# STM32U575 register map
File version: 1.4
CPU: CM33 r0p1, little endian, MPU, FPU, 4 interrupt priority bits
Registers are 32-bit, read-write, reset 0x0 unless marked. A register's access mark holds for its fields unless they carry their own. Offsets are from the block's base; [hi:lo] are bit positions; lines under a group give offsets from that group; {n}, {i} and the like mark numbered series; 'fields as' and 'values as' point back to an identical list.

## ADC1
Base 0x42028000
Same registers: SEC_ADC1 0x52028000
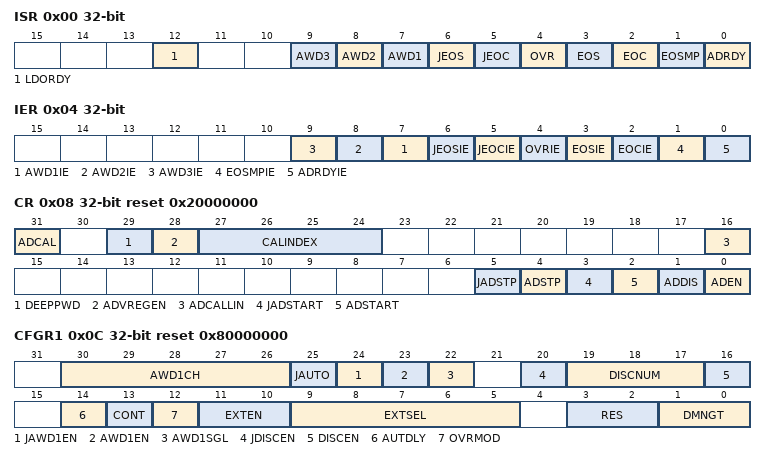
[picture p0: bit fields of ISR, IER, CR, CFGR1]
0x00 ISR access per field — ADC interrupt and status register
  [12] LDORDY ro — ADC voltage regulator ready This bit is set by hardware. It indicates that the ADC internal supply is ready. The ADC is available after tADCVREG_SETUP time.
    0=Disabled (ADC voltage regulator disabled); 1=Enabled (ADC voltage regulator enabled)
  [n+6] AWD{n} (n=1..3) rw — Analog watchdog {n} flag
    on read: 0=NoEvent (No analog watchdog x event occurred (or the flag event was already acknowledged and cleared by software)); 1=Event (Analog watchdog x event occurred) | on write: 1=Clear the analog watchdog x event flag
  [6] JEOS rw — Injected channel end of sequence flag This bit is set by hardware at the end of the conversions of all injected channels in the group. It is cleared by software writing 1 to it.
    on read: 0=NotComplete (Injected conversion sequence not complete (or the flag event was already acknowledged and cleared by software)); 1=Complete (Injected conversions sequence complete) | on write: 1=Clear the injected conversion sequence flag
  [5] JEOC rw — Injected channel end of conversion flag This bit is set by hardware at the end of each injected conversion of a channel when a new data is available in the corresponding ADC_JDRy register. It is cleared by software writing 1 to it or by reading the corresponding ADC_JDRy register
    on read: 0=NotComplete (Injected channel conversion not complete (or the flag event was already acknowledged and cleared by software)); 1=Complete (Injected channel conversion complete) | on write: 1=Clear the injected channel conversion flag
  [4] OVR rw — ADC overrun This bit is set by hardware when an overrun occurs on a regular channel, meaning that a new conversion has completed while the EOC flag was already set. It is cleared by software writing 1 to it.
    on read: 0=No overrun occurred (or the flag event was already acknowledged and cleared by software); 1=Overrun has occurred | on write: 1=Clear the overrun flag
  [3] EOS rw — End of regular sequence flag This bit is set by hardware at the end of the conversions of a regular sequence of channels. It is cleared by software writing 1 to it.
    on read: 0=NotComplete (Regular conversions sequence not complete (or the flag event was already acknowledged and cleared by software)); 1=Complete (Regular conversions sequence complete) | on write: 1=Clear the regular conversion sequence flag
  [2] EOC rw — End of conversion flag This bit is set by hardware at the end of each regular conversion of a channel when a new data is available in the ADC_DR register. It is cleared by software writing 1 to it or by reading the ADC_DR register
    on read: 0=NotComplete (Regular channel conversion not complete (or the flag event was already acknowledged and cleared by software)); 1=Complete (Regular channel conversion complete) | on write: 1=Clear the regular channel conversion flag
  [1] EOSMP rw — End of sampling flag This bit is set by hardware during the conversion of any channel (only for regular channels), at the end of the sampling phase.
    on read: 0=NotAtEnd (Not at the end of the sampling phase (or the flag event was already acknowledged and cleared by software)); 1=AtEnd (End of sampling phase reached) | on write: 1=Clear the sampling phase flag
  [0] ADRDY rw — ADC ready This bit is set by hardware after the ADC has been enabled (bit ADEN = 1) and when the ADC reaches a state where it is ready to accept conversion requests. It is cleared by software writing 1 to it.
    on read: 0=NotReady (ADC not yet ready to start conversion (or the flag event was already acknowledged and cleared by software)); 1=Ready (ADC is ready to start conversion) | on write: 1=Clear the ADC ready flag
0x04 IER — ADC interrupt enable register
  [n+6] AWD{n}IE (n=1..3) — Analog watchdog {n} interrupt enable
    0=Disabled (Analog watchdog x interrupt disabled); 1=Enabled (Analog watchdog x interrupt enabled)
  [6] JEOSIE — End of injected sequence of conversions interrupt enable This bit is set and cleared by software to enable/disable the end of injected sequence of conversions interrupt. Note: Software is allowed to write this bit only when JADSTART = 0 (which ensures that no injected conversion is ongoing).
    0=Disabled (JEOS interrupt disabled); 1=Enabled (JEOS interrupt enabled. An interrupt is generated when the JEOS bit is set.)
  [5] JEOCIE — End of injected conversion interrupt enable This bit is set and cleared by software to enable/disable the end of an injected conversion interrupt. Note: Software is allowed to write this bit only when JADSTART = 0 (which ensures that no regular conversion is ongoing).
    0=Disabled (JEOC interrupt disable); 1=Enabled (JEOC interrupt enabled. An interrupt is generated when the JEOC bit is set.)
  [4] OVRIE — Overrun interrupt enable This bit is set and cleared by software to enable/disable the Overrun interrupt of a regular conversion. Note: Software is allowed to write this bit only when ADSTART = 0 (which ensures that no regular conversion is ongoing).
    0=Disabled (Overrun interrupt disabled); 1=Enabled (Overrun interrupt enabled. An interrupt is generated when the OVR bit is set.)
  [3] EOSIE — End of regular sequence of conversions interrupt enable This bit is set and cleared by software to enable/disable the end of regular sequence of conversions interrupt. Note: Software is allowed to write this bit only when ADSTART = 0 (which ensures that no regular conversion is ongoing).
    0=Disabled (EOS interrupt disabled); 1=Enabled (EOS interrupt enabled. An interrupt is generated when the EOS bit is set.)
  [2] EOCIE — End of regular conversion interrupt enable This bit is set and cleared by software to enable/disable the end of a regular conversion interrupt. Note: Software is allowed to write this bit only when ADSTART = 0 (which ensures that no regular conversion is ongoing).
    0=Disabled (EOC interrupt disabled); 1=Enabled (EOC interrupt enabled. An interrupt is generated when the EOC bit is set.)
  [1] EOSMPIE — End of sampling flag interrupt enable for regular conversions This bit is set and cleared by software to enable/disable the end of the sampling phase interrupt for regular conversions. Note: Software is allowed to write this bit only when ADSTART = 0 (which ensures that no regular conversion is ongoing).
    0=Disabled (EOSMP interrupt disabled); 1=Enabled (EOSMP interrupt enabled. An interrupt is generated when the EOSMP bit is set.)
  [0] ADRDYIE — ADC ready interrupt enable This bit is set and cleared by software to enable/disable the ADC Ready interrupt. Note: Software is allowed to write this bit only when ADSTART = 0 and JADSTART = 0 (which ensures that no conversion is ongoing).
    0=Disabled (ADRDY interrupt disabled); 1=Enabled (ADRDY interrupt enabled. An interrupt is generated when the ADRDY bit is set.)
0x08 CR reset 0x20000000 — ADC control register
  [31] ADCAL — ADC calibration This bit is set by software to start the ADC calibration. It is cleared by hardware after calibration is complete. Note: The software is allowed to launch a calibration by setting ADCAL only when ADEN = 0.
    on read: 0=NotCalibrating (Calibration complete); 1=Calibrating (Calibration in progress) | on write: 1=StartCalibration (Calibrate the ADC)
  [29] DEEPPWD — Deep-power-down enable This bit is set and cleared by software to put the ADC in Deep-power-down mode. Note: The software is allowed to write this bit only when the ADC is disabled (ADCAL = 0, JADSTART = 0, JADSTP = 0, ADSTART = 0, ADSTP = 0, ADDIS = 0 and ADEN = 0).
    0=Disabled (ADC not in deep-power down); 1=Enabled (ADC in deep-power down)
  [28] ADVREGEN — ADC voltage regulator enable This bits is set by software to enable the ADC voltage regulator. Before performing any operation such as launching a calibration or enabling the ADC, the ADC voltage regulator must first be enabled and the software must wait for the regulator start-up time. For more details about the ADC voltage regulator enable and disable sequences, refer to (ADVREGEN). The software can program this bit field only when the ADC is disabled (ADCAL = 0, JADSTART = 0, ADSTART = 0, ADSTP = 0, ADDIS = 0 and ADEN = 0).
    values as ISR.LDORDY
  [27:24] CALINDEX — Calibration factor This bitfield controls the calibration factor to be read or written. Calibration index 0 is dedicated to single-ended and differential offsets, calibration index 1 to 7 to the linearity calibration factors, and index 8 to the internal offset: Others: Reserved, must not be used Note: ADC_CALFACT2[31:0] correspond to the location of CALINDEX[3:0] calibration factor data (see for details).
    0=OffsetCalFactor (Offset calibration factor); {v}=CalFactor{v} (Calibration factor {v}) (v=1..6); 7=CalFactor7 (Calibration factor 7 and (write access only) internal offset); 8=Internal offset (read access only); 9=Calibration mode selection
  [16] ADCALLIN — Linearity calibration This bit is set and cleared by software to enable the linearity calibration. Note: The software is allowed to write this bit only when the ADC is disabled and is not calibrating (ADCAL = 0, JADSTART = 0, JADSTP = 0, ADSTART = 0, ADSTP = 0, ADDIS = 0 and ADEN = 0).
    0=Disabled (Writing ADCAL launches a calibration without the linearity calibration); 1=Enabled (Writing ADCAL launches a calibration with he linearity calibration)
  [5] JADSTP — ADC stop of injected conversion command This bit is set by software to stop and discard an ongoing injected conversion (JADSTP Command). It is cleared by hardware when the conversion is effectively discarded and the ADC injected sequence and triggers can be re-configured. The ADC is then ready to accept a new start of injected conversions (JADSTART command). Note: The software is allowed to set JADSTP only when JADSTART = 1 and ADDIS = 0 (ADC is enabled and eventually converting an injected conversion and there is no pending request to disable the ADC). In Auto-injection mode (JAUTO = 1), setting ADSTP bit aborts both regular and injected conversions (do not use JADSTP)
    on read: 0=NotStopped (No ADC stop injected conversion command ongoing); 1=Stopped (ADSTP command is in progress) | on write: 1=Stop injected conversions ongoing
  [4] ADSTP — ADC stop of regular conversion command This bit is set by software to stop and discard an ongoing regular conversion (ADSTP Command). It is cleared by hardware when the conversion is effectively discarded and the ADC regular sequence and triggers can be re-configured. The ADC is then ready to accept a new start of regular conversions (ADSTART command). Note: The software is allowed to set ADSTP only when ADSTART = 1 and ADDIS = 0 (ADC is enabled and eventually converting a regular conversion and there is no pending request to disable the ADC). In Auto-injection mode (JAUTO = 1), setting ADSTP bit aborts both regular and injected conversions (do not use JADSTP).
    on read: 0=NotStopping (No ADC stop regular conversion command ongoing); 1=Stopping (ADSTP command is in progress) | on write: 1=StopConversion (Stop regular conversions ongoing)
  [3] JADSTART — ADC start of injected conversion This bit is set by software to start ADC conversion of injected channels. Depending on the configuration bits JEXTEN[1:0], a conversion starts immediately (software trigger configuration) or once an injected hardware trigger event occurs (hardware trigger configuration). It is cleared by hardware: in Single conversion mode when software trigger is selected (JEXTSEL = 0x0): at the assertion of the end of injected conversion sequence (JEOS) flag. in all cases: after the execution of the JADSTP command, at the same time as JADSTP is cleared by hardware. Note: The software is allowed to set JADSTART only when ADEN = 1 and ADDIS = 0 (ADC is enabled and there is no pending request to disable the ADC). In Auto-injection mode (JAUTO = 1), regular and auto-injected conversions are started by setting bit ADSTART (JADSTART must be kept cleared)
    on read: 0=NotActive (No ADC injected conversion is ongoing); 1=Active (ADC is operating and eventually converting an injected channel) | on write: 1=Start injected conversions
  [2] ADSTART — ADC start of regular conversion This bit is set by software to start ADC conversion of regular channels. Depending on the configuration bits EXTEN[1:0], a conversion starts immediately (software trigger configuration) or once a regular hardware trigger event occurs (hardware trigger configuration). It is cleared by hardware: in Single conversion mode (CONT = 0, DISCEN = 0) when software trigger is selected (EXTEN[1:0] = 0x0): at the assertion of the end of regular conversion sequence (EOS) flag. In Discontinuous conversion mode (CONT = 0, DISCEN = 1), when the software trigger is selected (EXTEN[1:0] = 0x0): at the end of conversion (EOC) flag. in all other cases: after the execution of the ADSTP command, at the same time that ADSTP is cleared by hardware. Note: The software is allowed to set ADSTART only when ADEN = 1 and ADDIS = 0 (ADC is enabled and there is no pending request to disable the ADC) In Auto-injection mode (JAUTO = 1), regular and auto-injected conversions are started by setting bit ADSTART (JADSTART must be kept cleared)
    on read: 0=NotActive (No ADC regular conversion is ongoing); 1=Active (ADC is operating and eventually converting a regular channel) | on write: 1=Start regular conversions
  [1] ADDIS — ADC disable command This bit is set by software to disable the ADC (ADDIS command) and put it into power-down state (OFF state). It is cleared by hardware once the ADC is effectively disabled (ADEN is also cleared by hardware at this time). Note: The software is allowed to set ADDIS only when ADEN = 1 and both ADSTART = 0 and JADSTART = 0 (which ensures that no conversion is ongoing)
    on read: 0=NotOngoing (No ADDIS command ongoing); 1=InProgress (An ADDIS command is in progress) | on write: 1=Disable the ADC
  [0] ADEN — ADC enable control This bit is set by software to enable the ADC. The ADC is effectively ready to operate once the flag ADRDY has been set. It is cleared by hardware when the ADC is disabled, after the execution of the ADDIS command. Note: The software is allowed to set ADEN only when all bits of ADC_CR registers are 0 (ADCAL = 0, JADSTART = 0, ADSTART = 0, ADSTP = 0, ADDIS = 0 and ADEN = 0) except for bit ADVREGEN which must be 1 (and the software must have wait for the startup time of the voltage regulator)
    on read: 0=Disabled (ADC is disabled); 1=Enabled (ADC is enabled) | on write: 1=Enabled (Enable the ADC)
0x0C CFGR1 reset 0x80000000 — ADC configuration register
  [30:26] AWD1CH range 0..19 — Analog watchdog 1 channel selection These bits are set and cleared by software. They select the input channel to be guarded by the analog watchdog. ..... Others: Reserved, must not be used Note: The channel selected by AWD1CH must be also selected into the SQRi or JSQRi registers. Software is allowed to write these bits only when ADSTART = 0 and JADSTART = 0 (which ensures that no conversion is ongoing).
  [25] JAUTO — Automatic injected group conversion This bit is set and cleared by software to enable/disable automatic injected group conversion after regular group conversion. Note: The software is allowed to write this bit only when ADSTART = 0 and JADSTART = 0 (which ensures that no regular nor injected conversion is ongoing).
    0=Disabled (Automatic injected group conversion disabled); 1=Enabled (Automatic injected group conversion enabled)
  [24] JAWD1EN — Analog watchdog 1 enable on injected channels This bit is set and cleared by software Note: The software is allowed to write this bit only when JADSTART = 0 (which ensures that no injected conversion is ongoing).
    0=Disabled (Analog watchdog 1 disabled on injected channels); 1=Enabled (Analog watchdog 1 enabled on injected channels)
  [23] AWD1EN — Analog watchdog 1 enable on regular channels This bit is set and cleared by software Note: The software is allowed to write this bit only when ADSTART = 0 (which ensures that no regular conversion is ongoing).
    0=Disabled (Analog watchdog 1 disabled on regular channels); 1=Enabled (Analog watchdog 1 enabled on regular channels)
  [22] AWD1SGL — Enable the watchdog 1 on a single channel or on all channels This bit is set and cleared by software to enable the analog watchdog on the channel identified by the AWD1CH[4:0] bits or on all the channels Note: The software is allowed to write these bits only when ADSTART = 0 and JADSTART = 0 (which ensures that no conversion is ongoing).
    0=AllChannels (Analog watchdog 1 enabled on all channels); 1=SingleChannel (Analog watchdog 1 enabled on a single channel)
  [20] JDISCEN — Discontinuous mode on injected channels This bit is set and cleared by software to enable/disable discontinuous mode on the injected channels of a group. Note: The software is allowed to write this bit only when JADSTART = 0 (which ensures that no injected conversion is ongoing). It is not possible to use both auto-injected mode and discontinuous mode simultaneously: the bits DISCEN and JDISCEN must be kept cleared by software when JAUTO is set.
    0=Disabled (Discontinuous mode on injected channels disabled); 1=Enabled (Discontinuous mode on injected channels enabled)
  [19:17] DISCNUM — Discontinuous mode channel count These bits are written by software to define the number of regular channels to be converted in discontinuous mode, after receiving an external trigger. ... Note: The software is allowed to write these bits only when ADSTART = 0 (which ensures that no regular conversion is ongoing).
    0=n1 (1 channel); {v}=n{v+1} ({v+1} channels) (v=1..7)
  [16] DISCEN — Discontinuous mode for regular channels This bit is set and cleared by software to enable/disable Discontinuous mode for regular channels. Note: It is not possible to have both discontinuous mode and continuous mode enabled: it is forbidden to set both DISCEN = 1 and CONT = 1. It is not possible to use both auto-injected mode and discontinuous mode simultaneously: the bits DISCEN and JDISCEN must be kept cleared by software when JAUTO is set. The software is allowed to write this bit only when ADSTART = 0 (which ensures that no regular conversion is ongoing).
    0=Disabled (Discontinuous mode for regular channels disabled); 1=Enabled (Discontinuous mode for regular channels enabled)
  [14] AUTDLY — Delayed conversion mode This bit is set and cleared by software to enable/disable the Auto Delayed Conversion mode.. Note: The software is allowed to write this bit only when ADSTART = 0 and JADSTART = 0 (which ensures that no conversion is ongoing).
    0=Disabled (Auto-delayed conversion mode off); 1=Enabled (Auto-delayed conversion mode on)
  [13] CONT — Single / continuous conversion mode for regular conversions This bit is set and cleared by software. If it is set, regular conversion takes place continuously until it is cleared. Note: It is not possible to have both discontinuous mode and continuous mode enabled: it is forbidden to set both DISCEN = 1 and CONT = 1. The software is allowed to write this bit only when ADSTART = 0 (which ensures that no regular conversion is ongoing).
    0=Single conversion mode; 1=Continuous conversion mode
  [12] OVRMOD — Overrun Mode This bit is set and cleared by software and configure the way data overrun is managed. Note: The software is allowed to write this bit only when ADSTART = 0 (which ensures that no regular conversion is ongoing).
    0=Preserve (ADC_DR register is preserved with the old data when an overrun is detected); 1=Overwrite (ADC_DR register is overwritten with the last conversion result when an overrun is detected)
  [11:10] EXTEN — External trigger enable and polarity selection for regular channels These bits are set and cleared by software to select the external trigger polarity and enable the trigger of a regular group. Note: The software is allowed to write these bits only when ADSTART = 0 (which ensures that no regular conversion is ongoing).
    0=Disabled (Hardware trigger detection disabled (conversions can be launched by software)); 1=RisingEdge (Hardware trigger detection on the rising edge); 2=FallingEdge (Hardware trigger detection on the falling edge); 3=BothEdges (Hardware trigger detection on both the rising and falling edges)
  [9:5] EXTSEL — External trigger selection for regular group These bits select the external event used to trigger the start of conversion of a regular group: ... Refer to the ADC external trigger for regular channels in signals for details on trigger mapping. Note: The software is allowed to write these bits only when ADSTART = 0 (which ensures that no regular conversion is ongoing).
    0=TIM1_OC1; 1=TIM1_OC2; 2=TIM1_OC3; 3=TIM2_OC2; 4=TIM3_TRGO; 5=TIM4_OC4; 6=EXTI11; 7=TIM8_TRGO; 8=TIM8_TRGO2; 9=TIM1_TRGO; 10=TIM1_TRGO2; 11=TIM2_TRGO; 12=TIM4_TRGO; 13=TIM6_TRGO; 14=TIM15_TRGO; 15=TIM3_OC4; 16=EXTI15; 18=LPTIM1_CH1; 19=LPTIM2_CH1; 20=LPTIM3_CH1; 21=LPTIM4_OUT
  [3:2] RES — Data resolution These bits are written by software to select the resolution of the conversion. Note: The software is allowed to write these bits only when ADSTART = 0 and JADSTART = 0 (which ensures that no conversion is ongoing).
    0=FourteenBit (14 bits); 1=TwelveBit (12 bits); 2=TenBit (10 bits); 3=EightBit (8 bits)
  [1:0] DMNGT — Data management configuration This bit is set and cleared by software to select how the ADC interface output data are managed. Note: The software is allowed to write this bit only when ADSTART = 0 and JADSTART = 0 (which ensures that no conversion is ongoing).
    0=DR (Store output data in DR only); 1=DMA One Shot Mode selected; 2=DFSDM (DFSDM mode selected); 3=DMA Circular Mode selected
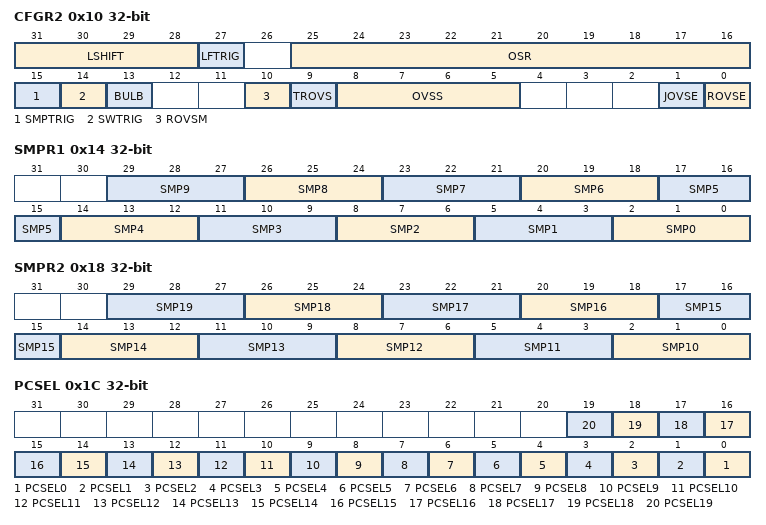
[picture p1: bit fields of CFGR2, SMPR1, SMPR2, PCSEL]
0x10 CFGR2 — ADC configuration register 2
  [31:28] LSHIFT — Left shift factor This bitfield is set and cleared by software to define the left shifting applied to the final result with or without oversampling. Note: The software is allowed to write this bit only when ADSTART = 0 (which ensures that no conversion is ongoing).
  [27] LFTRIG — Low-frequency trigger This bit is set and cleared by software Note: The software is allowed to write this bit only when ADSTART = 0 (which ensures that no conversion is ongoing).
    0=Disabled (Low-frequency trigger mode disabled); 1=Enabled (Low-frequency trigger mode enabled)
  [25:16] OSR — Oversampling ratio This bitfield is set and cleared by software to define the oversampling ratio. 2: 3x ... 1023: 1024x Note: The software is allowed to write this bit only when ADSTART = 0 (which ensures that no conversion is ongoing).
  [15] SMPTRIG — Sampling time control trigger mode This bit is set and cleared by software to enable the sampling time control trigger mode. The sampling time starts on the trigger rising edge, and the conversion on the trigger falling edge. EXTEN[1:0] bits must be set to 01. BULB bit must not be set when the SMPTRIG bit is set. When EXTEN[1:0] bits is set to 00, set SWTRIG to start the sampling and clear SWTRIG bit to start the conversion. Note: The software is allowed to write this bit only when ADSTART = 0 (which ensures that no conversion is ongoing).
    0=Disabled (Sampling time control trigger mode disabled); 1=Enabled (Sampling time control trigger mode enabled)
  [14] SWTRIG — Software trigger bit for sampling time control trigger mode This bit is set and cleared by software to enable the bulb sampling mode. Note: The software is allowed to write this bit only when ADSTART = 0 (which ensures that no conversion is ongoing).
    0=Disabled (Software trigger starts the conversion for sampling time control trigger mode); 1=Enabled (Software trigger starts the sampling for sampling time control trigger mode)
  [13] BULB — Bulb sampling mode This bit is set and cleared by software to select the bulb sampling mode. SMPTRIG bit must not be set when the BULB bit is set. The very first ADC conversion is performed with the sampling time specified in SMPx bits. Note: The software is allowed to write this bit only when ADSTART = 0 (which ensures that no conversion is ongoing).
    0=Disabled (Bulb sampling mode disabled); 1=Enabled (Bulb sampling mode enabled. The sampling period starts just after the previous end of the conversion.)
  [10] ROVSM — Regular Oversampling mode This bit is set and cleared by software to select the regular oversampling mode. Note: The software is allowed to write this bit only when ADSTART = 0 (which ensures that no conversion is ongoing).
    0=Continued (When injected conversions are triggered, the oversampling is temporary stopped and continued after the injection sequence (oversampling buffer is maintained during injected sequence)); 1=Resumed (When injected conversions are triggered, the current oversampling is aborted and resumed from start after the injection sequence (oversampling buffer is zeroed by injected sequence start))
  [9] TROVS — Triggered Regular Oversampling This bit is set and cleared by software to enable triggered oversampling Note: The software is allowed to write this bit only when ADSTART = 0 (which ensures that no conversion is ongoing).
    0=Automatic (All oversampled conversions for a channel are done consecutively following a trigger); 1=Triggered (Each oversampled conversion for a channel needs a new trigger)
  [8:5] OVSS range 0..11 — Oversampling right shift This bit field is set and cleared by software to define the right shifting applied to the raw oversampling result. Others: Reserved, must not be used. Note: The software is allowed to write these bits only when ADSTART = 0 (which ensures that no conversion is ongoing).
  [1] JOVSE — Injected Oversampling Enable This bit is set and cleared by software to enable injected oversampling. Note: The software is allowed to write this bit only when ADSTART = 0 and JADSTART = 0 (which ensures that no conversion is ongoing)
    0=Disabled (Injected oversampling disabled); 1=Enabled (Injected oversampling enabled)
  [0] ROVSE — Regular Oversampling Enable This bit is set and cleared by software to enable regular oversampling. Note: The software is allowed to write this bit only when ADSTART = 0 and JADSTART = 0 (which ensures that no conversion is ongoing)
    0=Disabled (Regular oversampling disabled); 1=Enabled (Regular oversampling enabled)
0x14 SMPR1 — ADC sample time register 1
  [3n+2:3n] SMP{n} (n=0..9) — Channel {n} sample time selection
    0=Cycles5 (5 ADC clock cycles); 1=Cycles6 (6 ADC clock cycles); 2=Cycles12 (12 ADC clock cycles); 3=Cycles20 (20 ADC clock cycles); 4=Cycles36 (36 ADC clock cycles); 5=Cycles68 (68 ADC clock cycles); 6=Cycles391 (391 ADC clock cycles); 7=Cycles814 (814 ADC clock cycles)
0x18 SMPR2 — ADC sample time register 2
  [3n-28:3n-30] SMP{n} (n=10..19) — Channel {n} sample time selection
    values as SMPR1.SMP0
0x1C PCSEL — ADC channel preselection register
  [all] fields
    0=NotPreselected (Input channel x is not preselected for conversion, the ADC conversion of this channel shows a wrong result.); 1=Preselected (Input channel x is preselected for conversion)
  [n] PCSEL{n} (n=0..19) — Channel i (VINP[i]) preselection These bits are written by software to preselect the input channel I/O instance to be converted. Note: The software is allowed to write these bits only when ADSTART = 0 and JADSTART = 0 (which ensures that no conversion is ongoing).
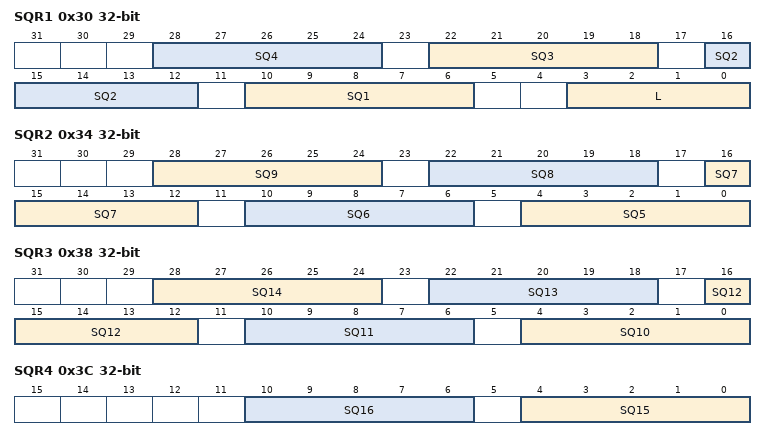
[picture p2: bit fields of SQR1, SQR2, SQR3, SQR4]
0x30 SQR1 — ADC regular sequence register 1
  [6n+4:6n] SQ{n} (n=1..4) — {n} conversion in regular sequence
  [3:0] L — Regular channel sequence length These bits are written by software to define the total number of conversions in the regular channel conversion sequence. ... Note: The software is allowed to write these bits only when ADSTART = 0 (which ensures that no regular conversion is ongoing).
0x34 SQR2 — ADC regular sequence register 2
  [6n-26:6n-30] SQ{n} (n=5..9) — {n} conversion in regular sequence
0x38 SQR3 — ADC regular sequence register 3
  [6n-56:6n-60] SQ{n} (n=10..14) — {n} conversion in regular sequence
0x3C SQR4 — ADC regular sequence register 4
  [6n-86:6n-90] SQ{n} (n=15..16) — {n} conversion in regular sequence
0x40 DR ro — ADC regular Data Register
  [31:0] RDATA — Regular data converted These bits are read-only. They contain the conversion result from the last converted regular channel. The data are left- or right-aligned as described in .
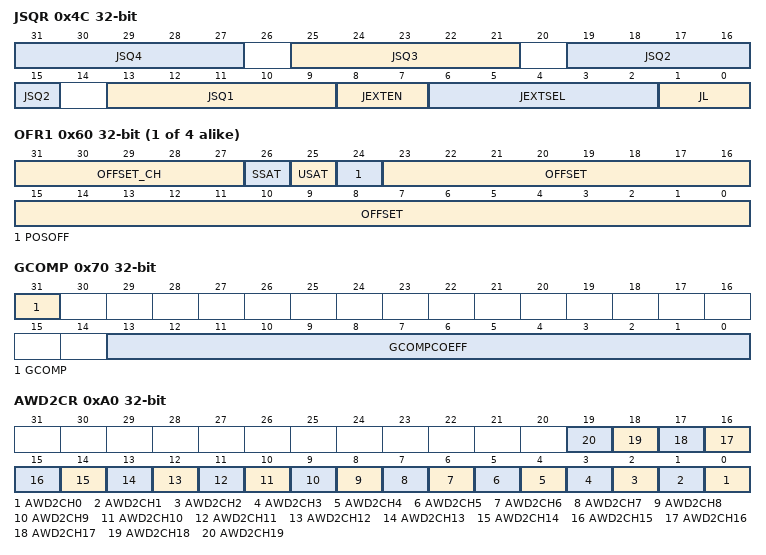
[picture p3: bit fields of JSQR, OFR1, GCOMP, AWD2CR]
0x4C JSQR — ADC injected sequence register
  [6n+7:6n+3] JSQ{n} (n=1..4) — {n} conversion in injected sequence
  [8:7] JEXTEN — External trigger enable and polarity selection for injected channels These bits are set and cleared by software to select the external trigger polarity and enable the trigger of an injected group. Note: The software is allowed to write these bits only when JADSTART = 0 (which ensures that no injected conversion is ongoing.
    values as CFGR1.EXTEN
  [6:2] JEXTSEL — External trigger selection for injected group These bits select the external event used to trigger the start of conversion of an injected group: ... Refer to the ADC external trigger for injected channels in internal signals for details on trigger mapping. Note: The software is allowed to write these bits only when JADSTART = 0 (which ensures that no injected conversion is ongoing.
    0=TIM1_TRGO; 1=TIM1_OC4; 2=TIM2_TRGO; 3=TIM2_OC1; 4=TIM3_OC4; 5=TIM4_TRGO; 6=EXTI15; 7=TIM8_OC4; 8=TIM1_TRGO2; 9=TIM8_TRGO; 10=TIM8_TRGO2; 11=TIM3_OC3; 12=TIM3_TRGO; 13=TIM3_OC1; 14=TIM6_TRGO; 15=TIM15_TRGO; 16=LPTIM1_CH2; 17=LPTIM2_CH2; 18=LPTIM3_CH1; 19=LPTIM4_OUT1
  [1:0] JL — Injected channel sequence length These bits are written by software to define the total number of conversions in the injected channel conversion sequence. Note: The software is allowed to write these bits only when JADSTART = 0 (which ensures that no injected conversion is ongoing.
{0x5C+4i} OFR{i} (i=1..4) — ADC offset register
  [31:27] OFFSET_CH — Channel selection for the data offset y These bits are written by software to define the channel to which the offset programmed into OFFSETy[25:0] bits applies. Note: The software is allowed to write these bits only when ADSTART = 0 and JADSTART = 0 (which ensures that no conversion is ongoing). If OFFSETy_EN bit is set, it is not allowed to select the same channel in different ADC_OFRy registers.
  [26] SSAT — Signed saturation enable This bit is written by software to enable or disable the Signed saturation feature. (see OFFSETy_CH, OVSS, LSHIFT, USAT, SSAT) for details). Note: The software is allowed to write this bit only when ADSTART = 0 and JADSTART = 0 (which ensures that no conversion is ongoing).
    0=Disabled (Offset is subtracted maintaining data integrity and extending converted data size (9-bit and 15-bit signed format)); 1=Enabled (Offset is subtracted and result is saturated to maintain converted data size)
  [25] USAT — Unsigned saturation enable This bit is written by software to enable or disable the unsigned saturation feature. Note: The software is allowed to write this bit only when ADSTART = 0 and JADSTART = 0 (which ensures that no conversion is ongoing).
    0=Disabled (Offset is subtracted maintaining data integrity and keeping converted data size); 1=Enabled (Offset is subtracted and result is saturated to maintain converted data size)
  [24] POSOFF — offset sign This bit is set and cleared by software to enable the positive offset. Note: The software is allowed to write these bits only when ADSTART = 0 and JADSTART = 0 (which ensures that no conversion is ongoing).
    0=Negative offset; 1=Positive offset
  [23:0] OFFSET — Data offset y for the channel programmed into OFFSETy_CH[4:0] bits These bits are written by software to define the offset y to be subtracted from the raw converted data when converting a channel (regular or injected). The channel to which the data offset y applies must be programmed to the OFFSETy_CH[4:0] bits. The conversion result can be read from in the ADC_DR (regular conversion) or from in the ADC_JDRyi registers (injected conversion). When OFFSETy[21:0] bitfield is reset, the offset compensation is disabled. Note: The software is allowed to write these bits only when ADSTART = 0 and JADSTART = 0 (which ensures that no conversion is ongoing). If several offsets (OFFSETy) point to the same channel, only the offset with the lowest y value is considered for the subtraction. For example, if OFFSET1_CH[4:0] = 4 and OFFSET2_CH[4:0] = 4, this is OFFSET1[25:0] that is subtracted when converting channel 4.
0x70 GCOMP — ADC gain compensation register
  [31] GCOMP — Gain compensation mode This bit is set and cleared by software to enable the gain compensation mode. Note: The software is allowed to write this bit only when ADSTART = 0 (which ensures that no conversion is ongoing).
    0=Disabled (Regular ADC operating mode); 1=Enabled (Gain compensation enabled and applied to all channels)
  [13:0] GCOMPCOEFF — Gain compensation coefficient These bits are set and cleared by software to program the gain compensation coefficient. ... ... The coefficient is divided by 4096 to get the gain factor ranging from 0 to 3.999756. Note: This gain compensation is only applied when GCOMP bit of ADCx_CFGR2 register is 1.
{0x7C+4i} JDR{i} (i=1..4) ro — ADC injected data register
  [31:0] JDATA — Injected data These bits are read-only. They contain the conversion result from injected channel y. The data are left -or right-aligned as described in .
0xA0 AWD2CR access not given — ADC analog watchdog 2 configuration register
  [n] AWD2CH{n} (n=0..19) — Analog watchdog 2 channel selection These bits are set and cleared by software. They enable and select the input channels to be guarded by the analog watchdog 2. AWD2CH[i] = 0: ADC analog input channel-i is not monitored by AWD2 AWD2CH[i] = 1: ADC analog input channel-i is monitored by AWD2 When AWD2CH[19:0] = 000..0, the analog Watchdog 2 is disabled Note: The channels selected by AWD2CH must be also selected into the SQRi or JSQRi registers. Software is allowed to write these bits only when ADSTART = 0 and JADSTART = 0 (which ensures that no conversion is ongoing).
    0=Disabled (ADC analog input channel x is not monitored by AWDy); 1=Enabled (ADC analog input channel x is monitored by AWDy)
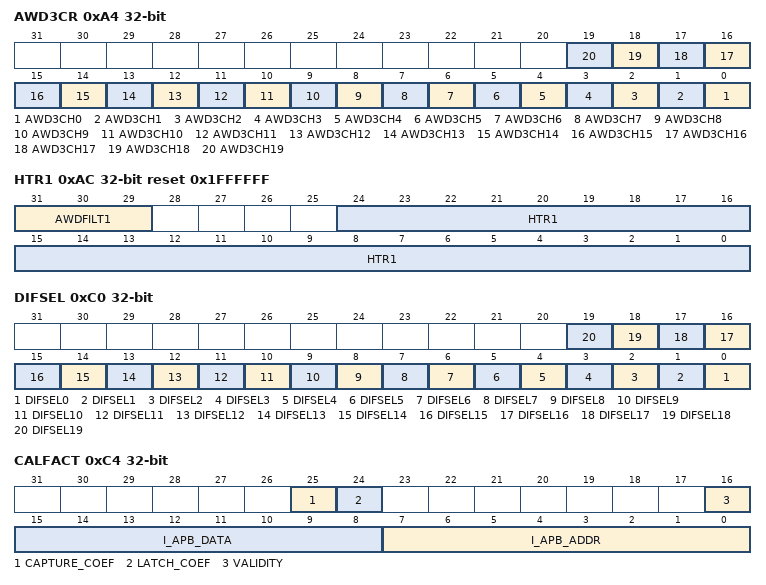
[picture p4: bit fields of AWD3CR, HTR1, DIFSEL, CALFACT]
0xA4 AWD3CR access not given — ADC analog watchdog 3 configuration register
  [n] AWD3CH{n} (n=0..19) — Analog watchdog 3 channel selection These bits are set and cleared by software. They enable and select the input channels to be guarded by the analog watchdog 3. AWD3CH[i] = 0: ADC analog input channel-i is not monitored by AWD3 AWD3CH[i] = 1: ADC analog input channel-i is monitored by AWD3 When AWD3CH[19:0] = 000..0, the analog Watchdog 3 is disabled Note: The channels selected by AWD3CH must be also selected into the SQRi or JSQRi registers. The software is allowed to write these bits only when ADSTART = 0 and JADSTART = 0 (which ensures that no conversion is ongoing).
    values as AWD2CR.AWD2CH0
0xA8 LTR1 — ADC watchdog threshold register 1
  [24:0] LTR1 — Analog watchdog 1 lower threshold These bits are written by software to define the lower threshold for the analog watchdog 1. Refer to AWD2CH, AWD3CH, AWD_HTRy, AWD_LTRy, AWDy).
0xAC HTR1 reset 0x1FFFFFF — ADC watchdog threshold register 1
  [31:29] AWDFILT1 — Analog watchdog filtering parameter This bit is set and cleared by software. ... Note: The software is allowed to write this bit only when ADSTART = 0 and JADSTART = 0 (which ensures that no conversion is ongoing).
    0=NoFiltering; 1=Detections2 (Two consecutive detections generates an AWDx flag or an interrupt); 2=Detections3 (Three consecutive detections generates an AWDx flag or an interrupt); 3=Detections4 (Four consecutive detections generates an AWDx flag or an interrupt); 4=Detections5 (Five consecutive detections generates an AWDx flag or an interrupt); 5=Detections6 (Six consecutive detections generates an AWDx flag or an interrupt); 6=Detections7 (Seven consecutive detections generates an AWDx flag or an interrupt); 7=Detections8 (Eight consecutive detections generates an AWDx flag or an interrupt)
  [24:0] HTR1 — Analog watchdog 1 higher threshold These bits are written by software to define the higher threshold for the analog watchdog 1. Refer to AWD2CH, AWD3CH, AWD_HTRy, AWD_LTRy, AWDy).
0xB0 LTR2 — ADC watchdog lower threshold register 2
  [24:0] LTR2 — Analog watchdog 2 lower threshold These bits are written by software to define the lower threshold for the analog watchdog 2. Refer to AWD2CH, AWD3CH, AWD_HTRy, AWD_LTRy, AWDy).
0xB4 HTR2 reset 0x1FFFFFF — ADC watchdog higher threshold register 2
  [24:0] HTR2 — Analog watchdog 2 higher threshold These bits are written by software to define the higher threshold for the analog watchdog 2. Refer to AWD2CH, AWD3CH, AWD_HTRy, AWD_LTRy, AWDy).
0xB8 LTR3 — ADC watchdog lower threshold register 3
  [24:0] LTR3 — Analog watchdog 3 lower threshold These bits are written by software to define the lower threshold for the analog watchdog 3. Refer to AWD2CH, AWD3CH, AWD_HTRy, AWD_LTRy, AWDy).
0xBC HTR3 reset 0x1FFFFFF — ADC watchdog higher threshold register 3
  [24:0] HTR3 — Analog watchdog 3 higher threshold These bits are written by software to define the higher threshold for the analog watchdog 3. Refer to AWD2CH, AWD3CH, AWD_HTRy, AWD_LTRy, AWDy).
0xC0 DIFSEL access not given — ADC differential mode selection register
  [n] DIFSEL{n} (n=0..19) — Differential mode for channel {n}
    0=SingleEnded (ADC analog input channel x is configured in single-ended mode); 1=Differential (ADC analog input channel x is configured in differential mode)
0xC4 CALFACT access per field — ADC user control register
  [25] CAPTURE_COEF rw — Calibration factor capture enable bit This bit enables the internal calibration factor capture.
    0=Disabled (Calibration factor not captured); 1=Enabled (Calibration factor available in CALFACT[31:0] bits, the calibration factor index being defined by CALINDEX[3:0] bits)
  [24] LATCH_COEF rw — Calibration factor latch enable bit This bit latches the calibration factor in the CALFACT[31:0] bits.
    0=NoEffect; 1=Latch (Calibration factor latched in the analog block on LATCH_COEF bit transition from 0 to 1. Prior to latching the calibration factor, CALFACT[31:0] bits must be programmed with the content of CALINDEX[3:0] bits.)
  [16] VALIDITY ro — Delayed write access status bit This bit indicates the communication status between the ADC digital and analog blocks.
    0=InProgress (Operation still in progress); 1=Complete (Operation complete)
  [15:8] I_APB_DATA ro — Delayed write access data This bitfield contains the data that are being written during delayed write accesses.
  [7:0] I_APB_ADDR ro — Delayed write access address This bitfield contains the address that is being written during delayed write accesses.
0xC8 CALFACT2 — ADC calibration factor register
  [31:0] CALFACT — Linearity or offset calibration factor These bits can be written either by hardware or by software. They contain the 32-bit offset or linearity calibration factor. When CAPTURE_COEF is set to 1, the calibration factor of the analog block is read back and stored in CALFACT[31:0], indexed by CALINDEX[3:0] bits. When LATCH_COEF is set to 1, the calibration factor of the analog block is updated with the value programmed in CALFACT[31:0], indexed by CALINDEX[3:0] bits. To read all calibration factors, perform nine accesses to the ADC_CALFACT2 register. To write all calibration factors, perform eight accesses to the ADC_CALFACT2 register. Note: The software is allowed to write these bits only when ADEN = 1, ADSTART = 0 and JADSTART = 0 (ADC is enabled and no calibration is ongoing and no conversion is ongoing).
